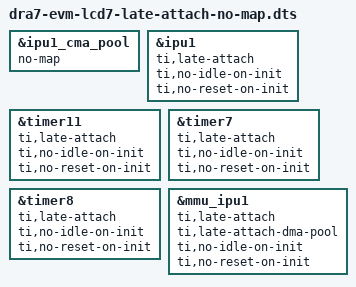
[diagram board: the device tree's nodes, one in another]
/*
 * Copyright (C) 2015 Texas Instruments Incorporated - http://www.ti.com/
 *
 * This program is free software; you can redistribute it and/or modify
 * it under the terms of the GNU General Public License version 2 as
 * published by the Free Software Foundation.
 */

#include "dra7-evm-lcd7.dts"

&ipu1_cma_pool {
	/delete-property/ reusable;
	no-map;
};

&ipu1 {
	ti,late-attach;
	ti,no-idle-on-init;
	ti,no-reset-on-init;
};

&timer11 {
	ti,late-attach;
	ti,no-idle-on-init;
	ti,no-reset-on-init;
};

&timer7 {
	ti,late-attach;
	ti,no-idle-on-init;
	ti,no-reset-on-init;
};

&timer8 {
	ti,late-attach;
	ti,no-idle-on-init;
	ti,no-reset-on-init;
};

&mmu_ipu1{
	ti,late-attach;
	ti,late-attach-dma-pool;
	ti,no-idle-on-init;
	ti,no-reset-on-init;
};
